# Template register map
Vendor: VendorName Co.Ltd; Series: SeriesName; File version: 1.2
CPU: CM7 r0p1, little endian, MPU, FPU, 4 interrupt priority bits
Registers are 32-bit, read-write, no defined reset value unless marked. A register's access mark holds for its fields unless they carry their own. Offsets are from the block's base; [hi:lo] are bit positions; {n}, {i} and the like mark numbered series.

## DBG — Debug Support
Base 0x4006E000
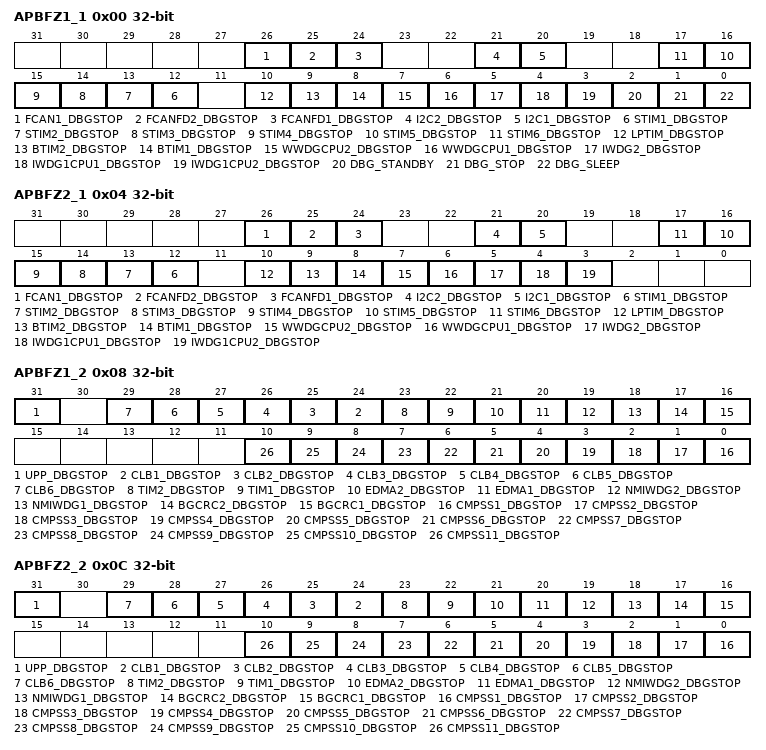
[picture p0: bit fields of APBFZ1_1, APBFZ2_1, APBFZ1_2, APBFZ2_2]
0x00 APBFZ1_1 — DBG mode core 1 control register 1
  [26] FCAN1_DBGSTOP — DBG FCAN1_DBGSTOP bit: FCAN1 debug mode stop operation 11
  [25] FCANFD2_DBGSTOP — DBG FCANFD2_DBGSTOP bit: FCANFD2 debug mode stop operation 11
  [24] FCANFD1_DBGSTOP — DBG FCANFD1_DBGSTOP bit: FCANFD1 debug mode stop operation 11
  [21] I2C2_DBGSTOP — DBG I2C2_DBGSTOP bit: I2C2 debug mode stop operation 11
  [20] I2C1_DBGSTOP — DBG I2C1_DBGSTOP bit: I2C1 debug mode stop operation 11
  [n+11] STIM{n}_DBGSTOP (n=1..6) — DBG STIM{n}_DBGSTOP bit: STIM{n} debug mode stop operation 11
  [10] LPTIM_DBGSTOP — DBG LPTIM_DBGSTOP bit: LPTIM debug mode stop operation 11
  [9] BTIM2_DBGSTOP — DBG BTIM2_DBGSTOP bit: BTIM2 debug mode stop operation 11
  [8] BTIM1_DBGSTOP — DBG BTIM1_DBGSTOP bit: BTIM1 debug mode stop operation 11
  [7] WWDGCPU2_DBGSTOP — DBG WWDGCPU2_DBGSTOP bit: WWDGCPU2 debug mode stop operation 11
  [6] WWDGCPU1_DBGSTOP — DBG WWDGCPU1_DBGSTOP bit: WWDGCPU1 debug mode stop operation 11
  [5] IWDG2_DBGSTOP — DBG IWDG2_DBGSTOP bit: IWDG2 debug mode stop operation 11
  [4] IWDG1CPU1_DBGSTOP — DBG IWDG1CPU1_DBGSTOP bit: IWDG1CPU1 debug mode stop operation 11
  [3] IWDG1CPU2_DBGSTOP — DBG IWDG1CPU2_DBGSTOP bit: IWDG1CPU2 debug mode stop operation 11
  [2] DBG_STANDBY — DBG DBG_STANDBY bit: debug mode standby 11
  [1] DBG_STOP — DBG DBG_STOP bit: debug mode stop 11
  [0] DBG_SLEEP — DBG DBG_SLEEP bit: debug mode sleep 11
0x04 APBFZ2_1 — DBG mode core 2 control register 1
  [26] FCAN1_DBGSTOP — DBG FCAN1_DBGSTOP bit: FCAN1 debug mode stop operation 21
  [25] FCANFD2_DBGSTOP — DBG FCANFD2_DBGSTOP bit: FCANFD2 debug mode stop operation 21
  [24] FCANFD1_DBGSTOP — DBG FCANFD1_DBGSTOP bit: FCANFD1 debug mode stop operation 21
  [21] I2C2_DBGSTOP — DBG I2C2_DBGSTOP bit: I2C2 debug mode stop operation 21
  [20] I2C1_DBGSTOP — DBG I2C1_DBGSTOP bit: I2C1 debug mode stop operation 21
  [n+11] STIM{n}_DBGSTOP (n=1..6) — DBG STIM{n}_DBGSTOP bit: STIM{n} debug mode stop operation 21
  [10] LPTIM_DBGSTOP — DBG LPTIM_DBGSTOP bit: LPTIM debug mode stop operation 21
  [9] BTIM2_DBGSTOP — DBG BTIM2_DBGSTOP bit: BTIM2 debug mode stop operation 21
  [8] BTIM1_DBGSTOP — DBG BTIM1_DBGSTOP bit: BTIM1 debug mode stop operation 21
  [7] WWDGCPU2_DBGSTOP — DBG WWDGCPU2_DBGSTOP bit: WWDGCPU2 debug mode stop operation 21
  [6] WWDGCPU1_DBGSTOP — DBG WWDGCPU1_DBGSTOP bit: WWDGCPU1 debug mode stop operation 21
  [5] IWDG2_DBGSTOP — DBG IWDG2_DBGSTOP bit: IWDG2 debug mode stop operation 21
  [4] IWDG1CPU1_DBGSTOP — DBG IWDG1CPU1_DBGSTOP bit: IWDG1CPU1 debug mode stop operation 21
  [3] IWDG1CPU2_DBGSTOP — DBG IWDG1CPU2_DBGSTOP bit: IWDG1CPU2 debug mode stop operation 21
0x08 APBFZ1_2 — DBG mode core 1 control register 2
  [31] UPP_DBGSTOP — DBG UPP_DBGSTOP bit: UPP debug mode stop operation 12
  [n+23] CLB{n}_DBGSTOP (n=1..6) — DBG CLB{n}_DBGSTOP bit: CLB{n} debug mode stop operation 12
  [23] TIM2_DBGSTOP — DBG TIM2_DBGSTOP bit: TIM2 debug mode stop operation 12
  [22] TIM1_DBGSTOP — DBG TIM1_DBGSTOP bit: TIM1 debug mode stop operation 12
  [21] EDMA2_DBGSTOP — DBG EDMA2_DBGSTOP bit: EDMA2 debug mode stop operation 12
  [20] EDMA1_DBGSTOP — DBG EDMA1_DBGSTOP bit: EDMA1 debug mode stop operation 12
  [19] NMIWDG2_DBGSTOP — DBG NMIWDG2_DBGSTOP bit: NMIWDG2 debug mode stop operation 12
  [18] NMIWDG1_DBGSTOP — DBG NMIWDG1_DBGSTOP bit: NMIWDG1 debug mode stop operation 12
  [17] BGCRC2_DBGSTOP — DBG BGCRC2_DBGSTOP bit: BGCRC2 debug mode stop operation 12
  [16] BGCRC1_DBGSTOP — DBG BGCRC1_DBGSTOP bit: BGCRC1 debug mode stop operation 12
  [n-1] CMPSS{n}_DBGSTOP (n=1..11) — DBG CMPSS{n}_DBGSTOP bit: CMPSS{n} debug mode stop operation 12
0x0C APBFZ2_2 — DBG mode core 2 control register 2
  [31] UPP_DBGSTOP — DBG UPP_DBGSTOP bit: UPP debug mode stop operation 22
  [n+23] CLB{n}_DBGSTOP (n=1..6) — DBG CLB{n}_DBGSTOP bit: CLB{n} debug mode stop operation 22
  [23] TIM2_DBGSTOP — DBG TIM2_DBGSTOP bit: TIM2 debug mode stop operation 22
  [22] TIM1_DBGSTOP — DBG TIM1_DBGSTOP bit: TIM1 debug mode stop operation 22
  [21] EDMA2_DBGSTOP — DBG EDMA2_DBGSTOP bit: EDMA2 debug mode stop operation 22
  [20] EDMA1_DBGSTOP — DBG EDMA1_DBGSTOP bit: EDMA1 debug mode stop operation 22
  [19] NMIWDG2_DBGSTOP — DBG NMIWDG2_DBGSTOP bit: NMIWDG2 debug mode stop operation 22
  [18] NMIWDG1_DBGSTOP — DBG NMIWDG1_DBGSTOP bit: NMIWDG1 debug mode stop operation 22
  [17] BGCRC2_DBGSTOP — DBG BGCRC2_DBGSTOP bit: BGCRC2 debug mode stop operation 22
  [16] BGCRC1_DBGSTOP — DBG BGCRC1_DBGSTOP bit: BGCRC1 debug mode stop operation 22
  [n-1] CMPSS{n}_DBGSTOP (n=1..11) — DBG CMPSS{n}_DBGSTOP bit: CMPSS{n} debug mode gstop operation 22
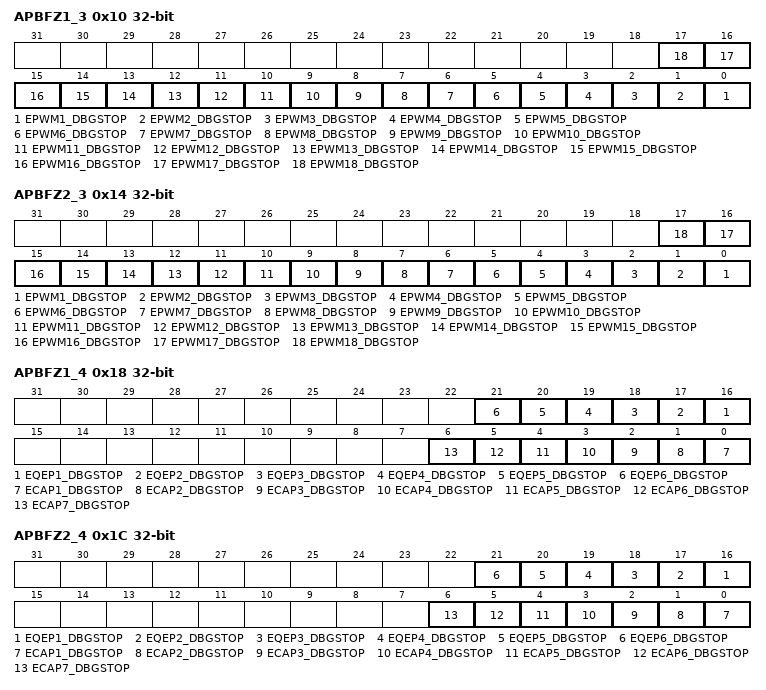
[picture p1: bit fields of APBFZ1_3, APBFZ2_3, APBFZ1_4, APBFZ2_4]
0x10 APBFZ1_3 — DBG mode core 1 control register 3
  [n-1] EPWM{n}_DBGSTOP (n=1..18) — DBG EPWM{n}_DBGSTOP bit: EPWM{n} debug mode stop operation 13
0x14 APBFZ2_3 — DBG mode core 2 control register 3
  [n-1] EPWM{n}_DBGSTOP (n=1..18) — DBG EPWM{n}_DBGSTOP bit: EPWM{n} debug mode stop operation 23
0x18 APBFZ1_4 — DBG mode core 1 control register 4
  [n+15] EQEP{n}_DBGSTOP (n=1..6) — DBG EQEP{n}_DBGSTOP bit: EQEP{n} debug mode stop operation 14
  [n-1] ECAP{n}_DBGSTOP (n=1..7) — DBG ECAP{n}_DBGSTOP bit: ECAP{n} debug mode stop operation 14
0x1C APBFZ2_4 — DBG mode core 2 control register 4
  [n+15] EQEP{n}_DBGSTOP (n=1..6) — DBG EQEP{n}_DBGSTOP bit: EQEP{n} debug mode stop operation 24
  [n-1] ECAP{n}_DBGSTOP (n=1..7) — DBG ECAP{n}_DBGSTOP bit: ECAP{n} debug mode stop operation 24
